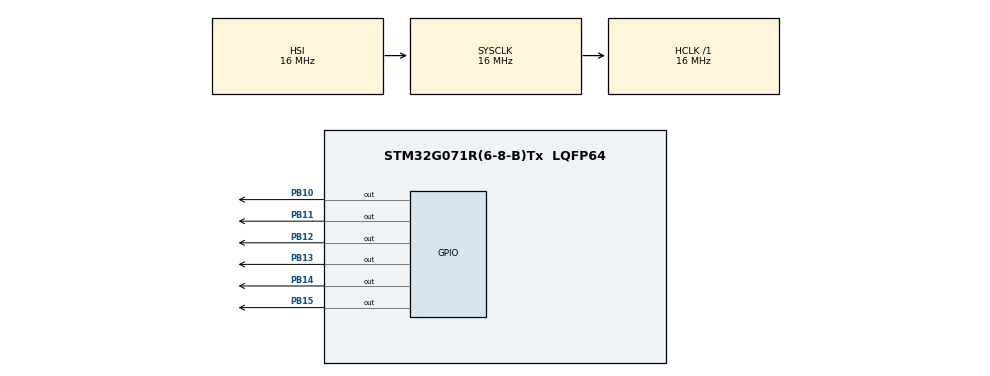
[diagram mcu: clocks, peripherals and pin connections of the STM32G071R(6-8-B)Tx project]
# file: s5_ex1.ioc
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Mcu.Family=STM32G0
Mcu.Name=STM32G071R(6-8-B)Tx
Mcu.Package=LQFP64
PB10.Signal=GPIO_Output
PB11.Signal=GPIO_Output
PB12.Signal=GPIO_Output
PB13.Signal=GPIO_Output
PB14.Signal=GPIO_Output
PB15.Signal=GPIO_Output
ProjectManager.HeapSize=0x200
ProjectManager.StackSize=0x400
ProjectManager.TargetToolchain=STM32CubeIDE
RCC.AHBFreq_Value=16000000
RCC.CortexFreq_Value=16000000
RCC.EXTERNAL_CLOCK_VALUE=48000
RCC.HCLKFreq_Value=16000000
RCC.HSE_VALUE=8000000
RCC.HSI_VALUE=16000000
RCC.LSE_VALUE=32768
RCC.SYSCLKFreq_VALUE=16000000
RCC.VCOOutputFreq_Value=128000000
VP_SYS_VS_DBSignals.Mode=DisableDeadBatterySignals
board=custom

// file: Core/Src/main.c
/* USER CODE BEGIN Header */
/**
  ******************************************************************************
  * @file           : main.c
  * @brief          : Main program body
  ******************************************************************************
  * @attention
  *
  * <h2><center>&copy; Copyright (c) 2022 STMicroelectronics.
  * All rights reserved.</center></h2>
  *
  * This software component is licensed by ST under BSD 3-Clause license,
  * the "License"; You may not use this file except in compliance with the
  * License. You may obtain a copy of the License at:
  *                        opensource.org/licenses/BSD-3-Clause
  *
  ******************************************************************************
  */
/* USER CODE END Header */
#include "main.h"
#include "lcd_txt.h"
void SystemClock_Config(void);
static void MX_GPIO_Init(void);
int main(void)
{
    HAL_Init();
    SystemClock_Config();
    MX_GPIO_Init();
    /* USER CODE BEGIN 2 */
    lcd_init();
    lcd_puts(0,0,"Hello STM32");

  while (1)
  {

  }
  /* USER CODE END 2 */
}

void SystemClock_Config(void)
{
  RCC_OscInitTypeDef RCC_OscInitStruct = {0};
  RCC_ClkInitTypeDef RCC_ClkInitStruct = {0};

  /** Configure the main internal regulator output voltage
  */
  HAL_PWREx_ControlVoltageScaling(PWR_REGULATOR_VOLTAGE_SCALE1);
  /** Initializes the RCC Oscillators according to the specified parameters
  * in the RCC_OscInitTypeDef structure.
  */
  RCC_OscInitStruct.OscillatorType = RCC_OSCILLATORTYPE_HSI;
  RCC_OscInitStruct.HSIState = RCC_HSI_ON;
  RCC_OscInitStruct.HSIDiv = RCC_HSI_DIV1;
  RCC_OscInitStruct.HSICalibrationValue = RCC_HSICALIBRATION_DEFAULT;
  RCC_OscInitStruct.PLL.PLLState = RCC_PLL_NONE;
  if (HAL_RCC_OscConfig(&RCC_OscInitStruct) != HAL_OK)
  {
    Error_Handler();
  }
  /** Initializes the CPU, AHB and APB buses clocks
  */
  RCC_ClkInitStruct.ClockType = RCC_CLOCKTYPE_HCLK|RCC_CLOCKTYPE_SYSCLK
                              |RCC_CLOCKTYPE_PCLK1;
  RCC_ClkInitStruct.SYSCLKSource = RCC_SYSCLKSOURCE_HSI;
  RCC_ClkInitStruct.AHBCLKDivider = RCC_SYSCLK_DIV1;
  RCC_ClkInitStruct.APB1CLKDivider = RCC_HCLK_DIV1;

  if (HAL_RCC_ClockConfig(&RCC_ClkInitStruct, FLASH_LATENCY_0) != HAL_OK)
  {
    Error_Handler();
  }
}

static void MX_GPIO_Init(void)
{
  GPIO_InitTypeDef GPIO_InitStruct = {0};

  /* GPIO Ports Clock Enable */
  __HAL_RCC_GPIOB_CLK_ENABLE();

  /*Configure GPIO pin Output Level */
  HAL_GPIO_WritePin(GPIOB, GPIO_PIN_10|GPIO_PIN_11|GPIO_PIN_12|GPIO_PIN_13
                          |GPIO_PIN_14|GPIO_PIN_15, GPIO_PIN_RESET);

  /*Configure GPIO pins : PB10 PB11 PB12 PB13
                           PB14 PB15 */
  GPIO_InitStruct.Pin = GPIO_PIN_10|GPIO_PIN_11|GPIO_PIN_12|GPIO_PIN_13
                          |GPIO_PIN_14|GPIO_PIN_15;
  GPIO_InitStruct.Mode = GPIO_MODE_OUTPUT_PP;
  GPIO_InitStruct.Pull = GPIO_NOPULL;
  GPIO_InitStruct.Speed = GPIO_SPEED_FREQ_LOW;
  HAL_GPIO_Init(GPIOB, &GPIO_InitStruct);

}

void Error_Handler(void)
{
  __disable_irq();
  while (1)
  {
  }
}

/************************ (C) COPYRIGHT STMicroelectronics *****END OF FILE****/
